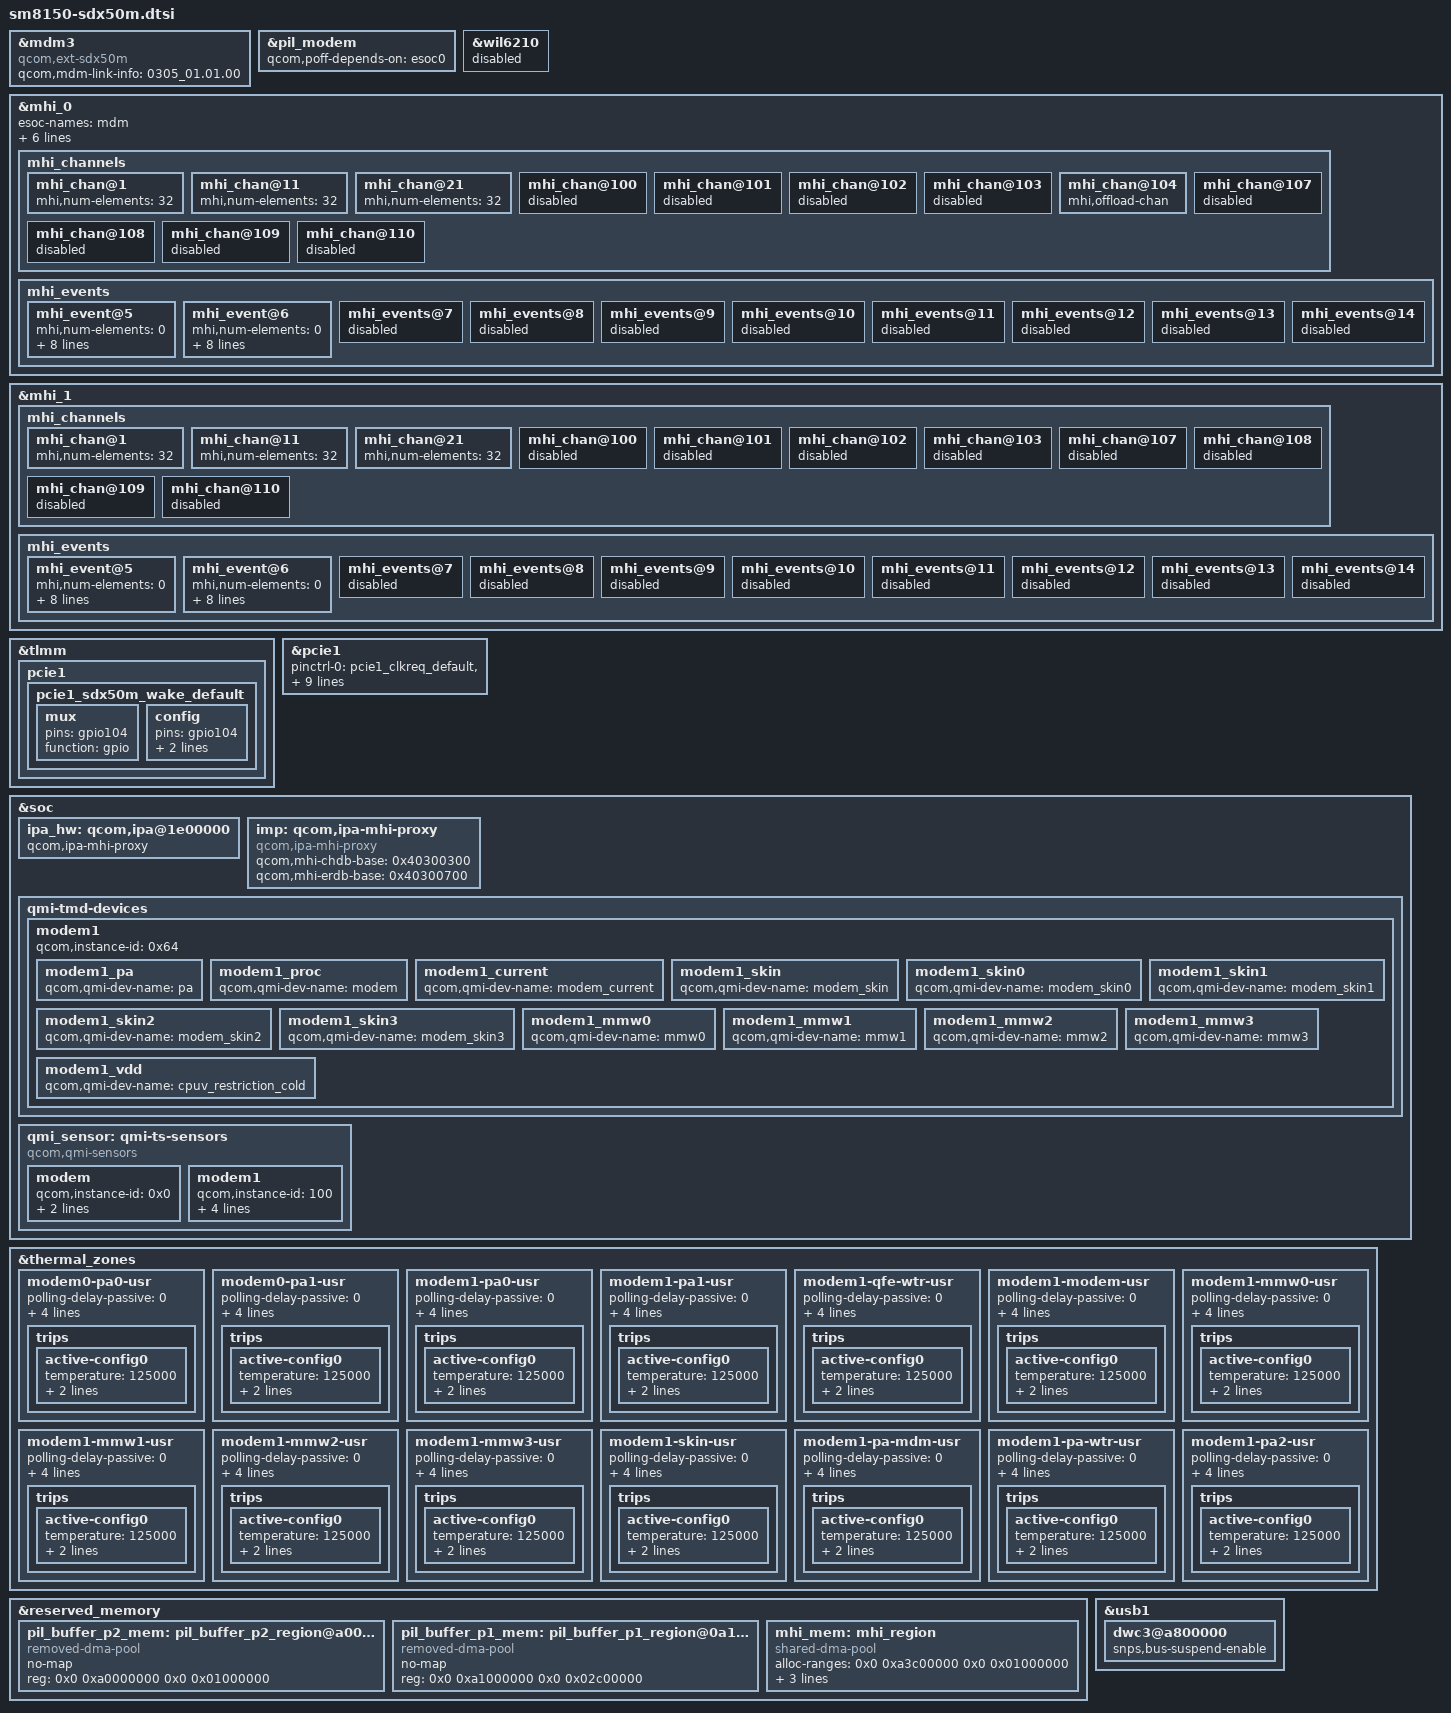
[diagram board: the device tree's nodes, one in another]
/* Copyright (c) 2018-2020, The Linux Foundation. All rights reserved.
 *
 * This program is free software; you can redistribute it and/or modify
 * it under the terms of the GNU General Public License version 2 and
 * only version 2 as published by the Free Software Foundation.
 *
 * This program is distributed in the hope that it will be useful,
 * but WITHOUT ANY WARRANTY; without even the implied warranty of
 * MERCHANTABILITY or FITNESS FOR A PARTICULAR PURPOSE.  See the
 * GNU General Public License for more details.
 */

&mdm3 {
	compatible = "qcom,ext-sdx50m";
	qcom,mdm-link-info = "0305_01.01.00";
};

&pil_modem {
	qcom,poff-depends-on = "esoc0";
};

&wil6210 {
	status = "disabled";
};

&mhi_0 {
	esoc-names = "mdm";
	esoc-0 = <&mdm3>;
	qcom,smmu-cfg = <0>;
	memory-region = <&mhi_mem>;
	mhi,use-bb;
	mhi,allow-m1; /* use legacy mode for suspends */
	qcom,addr-win = <0x0 0xa0000000 0x0 0xa4bfffff>;

	mhi_channels {
		mhi_chan@1 {
			mhi,num-elements = <32>;
		};

		mhi_chan@11 {
			mhi,num-elements = <32>;
		};

		mhi_chan@21 {
			mhi,num-elements = <32>;
		};

		mhi_chan@100 {
			status = "disabled";
		};

		mhi_chan@101 {
			status = "disabled";
		};

		mhi_chan@102 {
			status = "disabled";
		};

		mhi_chan@103 {
			status = "disabled";
		};

		mhi_chan@104 {
			mhi,offload-chan;
		};

		mhi_chan@107 {
			status = "disabled";
		};

		mhi_chan@108 {
			status = "disabled";
		};

		mhi_chan@109 {
			status = "disabled";
		};

		mhi_chan@110 {
			status = "disabled";
		};
	};

	mhi_events {
		mhi_event@5 {
			mhi,num-elements = <0>;
			mhi,intmod = <0>;
			mhi,msi = <5>;
			mhi,chan = <104>;
			mhi,priority = <1>;
			mhi,brstmode = <3>;
			mhi,hw-ev;
			mhi,client-manage;
			mhi,offload;
		};

		mhi_event@6 {
			mhi,num-elements = <0>;
			mhi,intmod = <0>;
			mhi,msi = <6>;
			mhi,chan = <105>;
			mhi,priority = <1>;
			mhi,brstmode = <3>;
			mhi,hw-ev;
			mhi,client-manage;
			mhi,offload;
		};

		mhi_events@7 {
			status = "disabled";
		};

		mhi_events@8 {
			status = "disabled";
		};

		mhi_events@9 {
			status = "disabled";
		};

		mhi_events@10 {
			status = "disabled";
		};

		mhi_events@11 {
			status = "disabled";
		};

		mhi_events@12 {
			status = "disabled";
		};

		mhi_events@13 {
			status = "disabled";
		};

		mhi_events@14 {
			status = "disabled";
		};
	};
};

&mhi_1 {
	mhi_channels {
		mhi_chan@1 {
			mhi,num-elements = <32>;
		};

		mhi_chan@11 {
			mhi,num-elements = <32>;
		};

		mhi_chan@21 {
			mhi,num-elements = <32>;
		};

		mhi_chan@100 {
			status = "disabled";
		};

		mhi_chan@101 {
			status = "disabled";
		};

		mhi_chan@102 {
			status = "disabled";
		};

		mhi_chan@103 {
			status = "disabled";
		};

		mhi_chan@107 {
			status = "disabled";
		};

		mhi_chan@108 {
			status = "disabled";
		};

		mhi_chan@109 {
			status = "disabled";
		};

		mhi_chan@110 {
			status = "disabled";
		};
	};

	mhi_events {
		mhi_event@5 {
			mhi,num-elements = <0>;
			mhi,intmod = <0>;
			mhi,msi = <5>;
			mhi,chan = <104>;
			mhi,priority = <1>;
			mhi,brstmode = <3>;
			mhi,hw-ev;
			mhi,client-manage;
			mhi,offload;
		};

		mhi_event@6 {
			mhi,num-elements = <0>;
			mhi,intmod = <0>;
			mhi,msi = <6>;
			mhi,chan = <105>;
			mhi,priority = <1>;
			mhi,brstmode = <3>;
			mhi,hw-ev;
			mhi,client-manage;
			mhi,offload;
		};

		mhi_events@7 {
			status = "disabled";
		};

		mhi_events@8 {
			status = "disabled";
		};

		mhi_events@9 {
			status = "disabled";
		};

		mhi_events@10 {
			status = "disabled";
		};

		mhi_events@11 {
			status = "disabled";
		};

		mhi_events@12 {
			status = "disabled";
		};

		mhi_events@13 {
			status = "disabled";
		};

		mhi_events@14 {
			status = "disabled";
		};
	};
};

&tlmm {
	pcie1 {
		pcie1_sdx50m_wake_default: pcie1_sdx50m_wake_default {
			mux {
				pins = "gpio104";
				function = "gpio";
			};

			config {
				pins = "gpio104";
				drive-strength = <2>;
				bias-disable;
			};
		};
	};
};

&pcie1 {
	pinctrl-0 = <&pcie1_clkreq_default
		&pcie1_perst_default
		&pcie1_sdx50m_wake_default>;

	iommu-map = <0x0 &apps_smmu 0x1e00 0x1>,
		<0x100 &apps_smmu 0x1e7f 0x1>;

	qcom,msm-bus,name = "pcie1";
	qcom,msm-bus,num-cases = <2>;
	qcom,msm-bus,num-paths = <1>;
	qcom,msm-bus,vectors-KBps =
		<100 512 0 0>,
		<100 512 4500000 0>;
};

&soc {
	ipa_hw: qcom,ipa@1e00000 {
		qcom,ipa-mhi-proxy;
	};

	imp: qcom,ipa-mhi-proxy {
		compatible = "qcom,ipa-mhi-proxy";
		qcom,mhi-chdb-base = <0x40300300>;
		qcom,mhi-erdb-base = <0x40300700>;
	};

	qmi-tmd-devices {
		modem1 {
			qcom,instance-id = <0x64>;

			modem1_pa: modem1_pa {
				qcom,qmi-dev-name = "pa";
				#cooling-cells = <2>;
			};

			modem1_proc: modem1_proc {
				qcom,qmi-dev-name = "modem";
				#cooling-cells = <2>;
			};

			modem1_current: modem1_current {
				qcom,qmi-dev-name = "modem_current";
				#cooling-cells = <2>;
			};

			modem1_skin: modem1_skin {
				qcom,qmi-dev-name = "modem_skin";
				#cooling-cells = <2>;
			};

			modem1_skin0: modem1_skin0 {
				qcom,qmi-dev-name = "modem_skin0";
				#cooling-cells = <2>;
			};

			modem1_skin1: modem1_skin1 {
				qcom,qmi-dev-name = "modem_skin1";
				#cooling-cells = <2>;
			};

			modem1_skin2: modem1_skin2 {
				qcom,qmi-dev-name = "modem_skin2";
				#cooling-cells = <2>;
			};

			modem1_skin3: modem1_skin3 {
				qcom,qmi-dev-name = "modem_skin3";
				#cooling-cells = <2>;
			};

			modem1_mmw0: modem1_mmw0 {
				qcom,qmi-dev-name = "mmw0";
				#cooling-cells = <2>;
			};

			modem1_mmw1: modem1_mmw1 {
				qcom,qmi-dev-name = "mmw1";
				#cooling-cells = <2>;
			};

			modem1_mmw2: modem1_mmw2 {
				qcom,qmi-dev-name = "mmw2";
				#cooling-cells = <2>;
			};

			modem1_mmw3: modem1_mmw3 {
				qcom,qmi-dev-name = "mmw3";
				#cooling-cells = <2>;
			};

			modem1_vdd: modem1_vdd {
				qcom,qmi-dev-name = "cpuv_restriction_cold";
				#cooling-cells = <2>;
			};
		};
	};

	qmi_sensor: qmi-ts-sensors {
		compatible = "qcom,qmi-sensors";
		#thermal-sensor-cells = <1>;

		modem {
			qcom,instance-id = <0x0>;
			qcom,qmi-sensor-names = "pa",
						"pa_1",
						"qfe_pa0",
						"qfe_wtr0";
		};

		modem1 {
			qcom,instance-id = <100>;
			qcom,qmi-sensor-names = "pa",
						"pa_1",
						"pa_2",
						"qfe_pa0",
						"qfe_wtr0",
						"modem_tsens",
						"qfe_mmw0",
						"qfe_mmw1",
						"qfe_mmw2",
						"qfe_mmw3",
						"xo_therm",
						"qfe_pa_mdm",
						"qfe_pa_wtr";
		};
	};
};

&thermal_zones {
	modem0-pa0-usr {
		polling-delay-passive = <0>;
		polling-delay = <0>;
		thermal-governor = "user_space";
		thermal-sensors = <&qmi_sensor 0>;
		wake-capable-sensor;
		trips {
			active-config0 {
				temperature = <125000>;
				hysteresis = <1000>;
				type = "passive";
			};
		};
	};

	modem0-pa1-usr {
		polling-delay-passive = <0>;
		polling-delay = <0>;
		thermal-governor = "user_space";
		thermal-sensors = <&qmi_sensor 1>;
		wake-capable-sensor;
		trips {
			active-config0 {
				temperature = <125000>;
				hysteresis = <1000>;
				type = "passive";
			};
		};
	};

	modem1-pa0-usr {
		polling-delay-passive = <0>;
		polling-delay = <0>;
		thermal-governor = "user_space";
		thermal-sensors = <&qmi_sensor 100>;
		wake-capable-sensor;
		trips {
			active-config0 {
				temperature = <125000>;
				hysteresis = <1000>;
				type = "passive";
			};
		};
	};

	modem1-pa1-usr {
		polling-delay-passive = <0>;
		polling-delay = <0>;
		thermal-governor = "user_space";
		thermal-sensors = <&qmi_sensor 101>;
		wake-capable-sensor;
		trips {
			active-config0 {
				temperature = <125000>;
				hysteresis = <1000>;
				type = "passive";
			};
		};
	};

	modem1-qfe-wtr-usr {
		polling-delay-passive = <0>;
		polling-delay = <0>;
		thermal-governor = "user_space";
		thermal-sensors = <&qmi_sensor 104>;
		wake-capable-sensor;
		trips {
			active-config0 {
				temperature = <125000>;
				hysteresis = <1000>;
				type = "passive";
			};
		};
	};

	modem1-modem-usr {
		polling-delay-passive = <0>;
		polling-delay = <0>;
		thermal-governor = "user_space";
		thermal-sensors = <&qmi_sensor 105>;
		wake-capable-sensor;
		trips {
			active-config0 {
				temperature = <125000>;
				hysteresis = <1000>;
				type = "passive";
			};
		};
	};

	modem1-mmw0-usr {
		polling-delay-passive = <0>;
		polling-delay = <0>;
		thermal-governor = "user_space";
		thermal-sensors = <&qmi_sensor 106>;
		wake-capable-sensor;
		trips {
			active-config0 {
				temperature = <125000>;
				hysteresis = <1000>;
				type = "passive";
			};
		};
	};

	modem1-mmw1-usr {
		polling-delay-passive = <0>;
		polling-delay = <0>;
		thermal-governor = "user_space";
		thermal-sensors = <&qmi_sensor 107>;
		wake-capable-sensor;
		trips {
			active-config0 {
				temperature = <125000>;
				hysteresis = <1000>;
				type = "passive";
			};
		};
	};

	modem1-mmw2-usr {
		polling-delay-passive = <0>;
		polling-delay = <0>;
		thermal-governor = "user_space";
		thermal-sensors = <&qmi_sensor 108>;
		wake-capable-sensor;
		trips {
			active-config0 {
				temperature = <125000>;
				hysteresis = <1000>;
				type = "passive";
			};
		};
	};

	modem1-mmw3-usr {
		polling-delay-passive = <0>;
		polling-delay = <0>;
		thermal-governor = "user_space";
		thermal-sensors = <&qmi_sensor 109>;
		wake-capable-sensor;
		trips {
			active-config0 {
				temperature = <125000>;
				hysteresis = <1000>;
				type = "passive";
			};
		};
	};

	modem1-skin-usr {
		polling-delay-passive = <0>;
		polling-delay = <0>;
		thermal-governor = "user_space";
		thermal-sensors = <&qmi_sensor 110>;
		wake-capable-sensor;
		trips {
			active-config0 {
				temperature = <125000>;
				hysteresis = <1000>;
				type = "passive";
			};
		};
	};

	modem1-pa-mdm-usr {
		polling-delay-passive = <0>;
		polling-delay = <0>;
		thermal-governor = "user_space";
		thermal-sensors = <&qmi_sensor 111>;
		wake-capable-sensor;
		trips {
			active-config0 {
				temperature = <125000>;
				hysteresis = <1000>;
				type = "passive";
			};
		};
	};

	modem1-pa-wtr-usr {
		polling-delay-passive = <0>;
		polling-delay = <0>;
		thermal-governor = "user_space";
		thermal-sensors = <&qmi_sensor 112>;
		wake-capable-sensor;
		trips {
			active-config0 {
				temperature = <125000>;
				hysteresis = <1000>;
				type = "passive";
			};
		};
	};

	modem1-pa2-usr {
		polling-delay-passive = <0>;
		polling-delay = <0>;
		thermal-governor = "user_space";
		thermal-sensors = <&qmi_sensor 102>;
		wake-capable-sensor;
		trips {
			active-config0 {
				temperature = <125000>;
				hysteresis = <1000>;
				type = "passive";
			};
		};
	};
};

&reserved_memory {
	#address-cells = <2>;
	#size-cells = <2>;

	pil_buffer_p2_mem: pil_buffer_p2_region@a0000000 {
		compatible = "removed-dma-pool";
		no-map;
		reg = <0x0 0xa0000000 0x0 0x01000000>;
	};

	pil_buffer_p1_mem: pil_buffer_p1_region@0a1000000 {
		compatible = "removed-dma-pool";
		no-map;
		reg = <0x0 0xa1000000 0x0 0x02c00000>;
	};

	mhi_mem: mhi_region {
		 compatible = "shared-dma-pool";
		 alloc-ranges = <0x0 0xa3c00000 0x0 0x01000000>;
		 alignment = <0x0 0x400000>;
		 size = <0x0 0x01000000>;
		 no-map;
	};
};

&usb1 {
	dwc3@a800000 {
		snps,bus-suspend-enable;
	};
};
